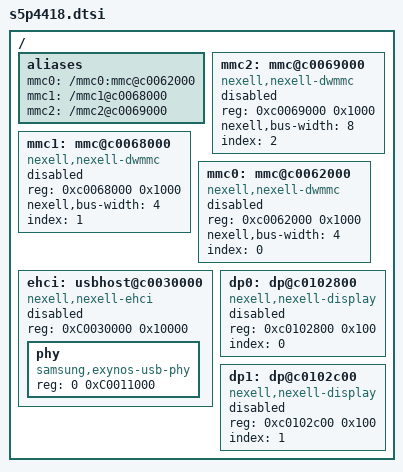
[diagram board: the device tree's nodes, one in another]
/*
 * (C) Copyright 2016 Nexell
 * Youngbok, Park <park@nexell.co.kr>
 *
 * SPDX-License-Identifier:      GPL-2.0+
 */

#include "skeleton.dtsi"
/ {
	aliases {
		mmc0 = "/mmc0:mmc@c0062000";
		mmc1 = "/mmc1@c0068000";
		mmc2 = "/mmc2@c0069000";
	};

	mmc2:mmc@c0069000 {
		#address-cells = <1>;
		#size-cells = <0>;
		compatible = "nexell,nexell-dwmmc";
		reg = <0xc0069000 0x1000>;
		nexell,bus-width = <8>;
		index = <2>;
		status = "disabled";
	};

	mmc1:mmc@c0068000 {
		#address-cells = <1>;
		#size-cells = <0>;
		compatible = "nexell,nexell-dwmmc";
		reg = <0xc0068000 0x1000>;
		nexell,bus-width = <4>;
		index = <1>;
		status = "disabled";
	};

	mmc0:mmc@c0062000 {
		#address-cells = <1>;
		#size-cells = <0>;
		compatible = "nexell,nexell-dwmmc";
		reg = <0xc0062000 0x1000>;
		nexell,bus-width = <4>;
		index = <0>;
		status = "disabled";
	};

	ehci:usbhost@c0030000 {
		compatible = "nexell,nexell-ehci";
		reg = <0xC0030000 0x10000>;
		#address-cells = <1>;
		#size-cells = <1>;
		status = "disabled";
		phy {
			compatible = "samsung,exynos-usb-phy";
			reg = <0 0xC0011000>;
		};
	};

	dp0:dp@c0102800 {
		#address-cells = <1>;
		#size-cells = <0>;
		compatible = "nexell,nexell-display";
		reg = <0xc0102800 0x100>;
		index = <0>;
		status = "disabled";
	};

	dp1:dp@c0102c00 {
		#address-cells = <1>;
		#size-cells = <0>;
		compatible = "nexell,nexell-display";
		reg = <0xc0102c00 0x100>;
		index = <1>;
		status = "disabled";
	};
};
